AUTOSAR XML (schema 00051)
standard types defined: uint16, uint32, float32, boolean, sint16
package /Components
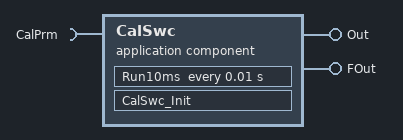
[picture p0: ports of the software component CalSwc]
  application sw component type CalSwc
    require port CalPrm: parameter-require-com-spec{init-value=CalPrm_Gain:99, parameter=Gain}, required-interface=CalPrm
    provide port Out: nonqueued-sender-com-spec{data-element=Out, init-value=0}, provided-interface=Out
    provide port FOut: nonqueued-sender-com-spec{data-element=FOut, init-value=0}, provided-interface=FOut
    behavior CalSwc_IB
      init event Event_CalSwc_Init: start-on-event=CalSwc_Init
      timing event Event_Run10ms: start-on-event=Run10ms, period=0.01
      runnable CalSwc_Init
      runnable Run10ms
        data-send-points:
          access SDP_Out: accessed-variable=Out.Out
          access SDP_FOut: accessed-variable=FOut.FOut
        parameter access CALPRM_CalPrm_Gain: accessed-parameter=CalPrm.Gain
        parameter access CALPRM_CalPrm_Table: accessed-parameter=CalPrm.Table
package /Interfaces
  parameter interface CalPrm
    6 x parameter data prototype, all with sw-calibration-access=READ-WRITE:
      Gain: category=VALUE, type=uint16
      Table: category=ARRAY, type=rt_Array_uint16_4
      Factor: category=VALUE, type=UFIX16_SP001
      Temp: category=VALUE, type=SFIX16_S01_BN40
      Alpha: category=VALUE, type=float32
      Enable: category=VALUE, type=boolean
  sender receiver interface Out
    data Out: category=VALUE, type=uint32
  sender receiver interface FOut
    data FOut: category=VALUE, type=float32
package /DataTypes
  impl type UFIX16_SP001: category=VALUE, base-type=uint16
  impl type SFIX16_S01_BN40: category=VALUE, base-type=sint16
  impl type rt_Array_uint16_4: category=ARRAY
    element rt_Array_uint16_4: array-size=4, array-size-semantics=FIXED-SIZE, implementation-data-type=uint16
package /DataTypes/ApplDataTypes
  app type UFIX16_SP001: category=VALUE, sw-calibration-access=READ-WRITE, compu {phys=raw*0.001}
  app type SFIX16_S01_BN40: category=VALUE, sw-calibration-access=READ-WRITE, compu {phys=raw*0.1-40; unit degC}
package /DataTypes/DataTypeMappings
  data type mapping set CalSwcDataTypeMappingsSet
    data-type-maps:
      application-data-type=UFIX16_SP001, implementation-data-type=UFIX16_SP001
      application-data-type=SFIX16_S01_BN40, implementation-data-type=SFIX16_S01_BN40
package /DataTypes/Units
  unit NoUnit: factor-si-to-unit=1, offset-si-to-unit=0
  unit degC: display-name=degC, factor-si-to-unit=1, offset-si-to-unit=-273.15
